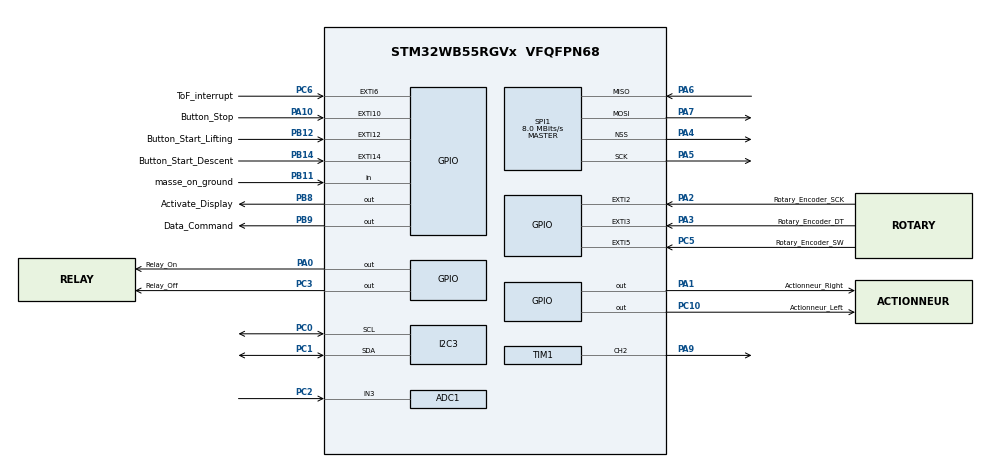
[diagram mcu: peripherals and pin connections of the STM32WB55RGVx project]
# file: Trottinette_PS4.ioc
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ADC1.Channel-0\#ChannelRegularConversion=ADC_CHANNEL_3
ADC1.ClockPrescaler=ADC_CLOCK_ASYNC_DIV4
ADC1.ContinuousConvMode=ENABLE
ADC1.DMAContinuousRequests=DISABLE
ADC1.NbrOfConversionFlag=1
ADC1.OffsetNumber-0\#ChannelRegularConversion=ADC_OFFSET_NONE
ADC1.Overrun=ADC_OVR_DATA_OVERWRITTEN
ADC1.Rank-0\#ChannelRegularConversion=1
ADC1.SamplingTime-0\#ChannelRegularConversion=ADC_SAMPLETIME_2CYCLES_5
ADC1.master=1
Dma.ADC1.0.Direction=DMA_PERIPH_TO_MEMORY
Dma.ADC1.0.EventEnable=DISABLE
Dma.ADC1.0.Instance=DMA1_Channel1
Dma.ADC1.0.MemDataAlignment=DMA_MDATAALIGN_HALFWORD
Dma.ADC1.0.MemInc=DMA_MINC_ENABLE
Dma.ADC1.0.Mode=DMA_CIRCULAR
Dma.ADC1.0.PeriphDataAlignment=DMA_PDATAALIGN_HALFWORD
Dma.ADC1.0.PeriphInc=DMA_PINC_DISABLE
Dma.ADC1.0.Polarity=HAL_DMAMUX_REQ_GEN_RISING
Dma.ADC1.0.Priority=DMA_PRIORITY_LOW
Dma.ADC1.0.RequestNumber=1
Dma.ADC1.0.SignalID=NONE
Dma.ADC1.0.SyncEnable=DISABLE
Dma.ADC1.0.SyncPolarity=HAL_DMAMUX_SYNC_NO_EVENT
Dma.ADC1.0.SyncRequestNumber=1
Dma.ADC1.0.SyncSignalID=NONE
Dma.Request0=ADC1
I2C3.Timing=0x00B07CB4
Mcu.Family=STM32WB
Mcu.Name=STM32WB55RGVx
Mcu.Package=VFQFPN68
NVIC.DMA1_Channel1_IRQn=true\:0\:0\:false\:false\:true\:false\:true\:true
NVIC.EXTI0_IRQn=true\:0\:0\:false\:false\:true\:true\:true\:true
NVIC.EXTI15_10_IRQn=true\:0\:0\:false\:false\:true\:true\:true\:true
NVIC.EXTI1_IRQn=true\:0\:0\:false\:false\:true\:true\:true\:true
NVIC.EXTI2_IRQn=true\:0\:0\:false\:false\:true\:true\:true\:true
NVIC.EXTI3_IRQn=true\:0\:0\:false\:false\:true\:true\:true\:true
NVIC.EXTI4_IRQn=true\:0\:0\:false\:false\:true\:true\:true\:true
NVIC.EXTI9_5_IRQn=true\:0\:0\:false\:false\:true\:true\:true\:true
NVIC.PriorityGroup=NVIC_PRIORITYGROUP_4
NVIC.SPI1_IRQn=true\:0\:0\:false\:false\:true\:true\:true\:true
NVIC.TIM2_IRQn=true\:0\:0\:false\:false\:true\:true\:true\:true
OSC_IN.GPIO_Label=RCC_OSC_IN
OSC_IN.Signal=RCC_OSC_IN
OSC_OUT.GPIO_Label=RCC_OSC_OUT
OSC_OUT.Signal=RCC_OSC_OUT
P-NUCLEO-WB55-NUCLEO.BUTTON=1
P-NUCLEO-WB55-NUCLEO.BUTTON2=1
P-NUCLEO-WB55-NUCLEO.BUTTON3=1
P-NUCLEO-WB55-NUCLEO.LD1=true
P-NUCLEO-WB55-NUCLEO.LD2=true
P-NUCLEO-WB55-NUCLEO.LD3=true
P-NUCLEO-WB55-NUCLEO.VCP=true
PA0.GPIO_Label=Relay_On
PA0.Signal=GPIO_Output
PA1.GPIO_Label=Actionneur_Right
PA1.Signal=GPIO_Output
PA10.GPIO_Label=Button_Stop
PA10.GPIO_ModeDefaultEXTI=GPIO_MODE_IT_FALLING
PA10.GPIO_PuPd=GPIO_PULLUP
PA10.Signal=GPXTI10
PA11.GPIO_Label=USB_DM
PA11.Signal=USB_DM
PA12.GPIO_Label=USB_DP
PA12.Signal=USB_DP
PA13.GPIO_Label=JTMS
PA13.Signal=SYS_JTMS-SWDIO
PA14.GPIO_Label=JTCK
PA14.Signal=SYS_JTCK-SWCLK
PA2.GPIO_Label=Rotary_Encoder_SCK
PA2.GPIO_ModeDefaultEXTI=GPIO_MODE_IT_RISING_FALLING
PA2.GPIO_PuPd=GPIO_PULLUP
PA2.Signal=GPXTI2
PA3.GPIO_Label=Rotary_Encoder_DT
PA3.GPIO_ModeDefaultEXTI=GPIO_MODE_IT_RISING_FALLING
PA3.GPIO_PuPd=GPIO_PULLUP
PA3.Signal=GPXTI3
PA4.Mode=NSS_Signal_Hard_Output
PA4.Signal=SPI1_NSS
PA5.Mode=Full_Duplex_Master
PA5.Signal=SPI1_SCK
PA6.Mode=Full_Duplex_Master
PA6.Signal=SPI1_MISO
PA7.Mode=Full_Duplex_Master
PA7.Signal=SPI1_MOSI
PA9.Signal=S_TIM1_CH2
PB11.GPIO_Label=masse_on_ground
PB11.Signal=GPIO_Input
PB12.GPIO_Label=Button_Start_Lifting
PB12.GPIO_ModeDefaultEXTI=GPIO_MODE_IT_FALLING
PB12.GPIO_PuPd=GPIO_PULLUP
PB12.Signal=GPXTI12
PB14.GPIO_Label=Button_Start_Descent
PB14.GPIO_ModeDefaultEXTI=GPIO_MODE_IT_FALLING
PB14.GPIO_PuPd=GPIO_PULLUP
PB14.Signal=GPXTI14
PB3.GPIO_Label=JTDO
PB3.Signal=SYS_JTDO-SWO
PB6.Signal=USART1_TX
PB7.Signal=USART1_RX
PB8.GPIO_Label=Activate_Display
PB8.Signal=GPIO_Output
PB9.GPIO_Label=Data_Command
PB9.Signal=GPIO_Output
PC0.Mode=I2C
PC0.Signal=I2C3_SCL
PC1.Mode=I2C
PC1.Signal=I2C3_SDA
PC10.GPIO_Label=Actionneur_Left
PC10.Signal=GPIO_Output
PC13.GPIO_Label=SYS_WKUP2
PC13.Signal=SYS_WKUP2
PC14-OSC32_IN.GPIO_Label=RCC_OSC32_IN
PC14-OSC32_IN.Signal=RCC_OSC32_IN
PC15-OSC32_OUT.GPIO_Label=RCC_OSC32_OUT
PC15-OSC32_OUT.Signal=RCC_OSC32_OUT
PC2.Signal=ADCx_IN3
PC3.GPIO_Label=Relay_Off
PC3.Signal=GPIO_Output
PC5.GPIO_Label=Rotary_Encoder_SW
PC5.GPIO_ModeDefaultEXTI=GPIO_MODE_IT_FALLING
PC5.GPIO_PuPd=GPIO_PULLUP
PC5.Signal=GPXTI5
PC6.GPIO_Label=ToF_interrupt
PC6.GPIO_ModeDefaultEXTI=GPIO_MODE_IT_FALLING
PC6.GPIO_PuPd=GPIO_PULLUP
PC6.Signal=GPXTI6
ProjectManager.HeapSize=0x200
ProjectManager.StackSize=0x400
ProjectManager.TargetToolchain=STM32CubeIDE
RCC.ADCCLockSelection=RCC_ADCCLKSOURCE_SYSCLK
RCC.ADCFreq_Value=32000000
RCC.AHBFreq_Value=32000000
RCC.APB1Freq_Value=32000000
RCC.APB1TimFreq_Value=32000000
RCC.APB2Freq_Value=32000000
RCC.APB2TimFreq_Value=32000000
RCC.APB3Freq_Value=16000000
RCC.CortexFreq_Value=32000000
RCC.HCLKFreq_Value=32000000
RCC.HSE_VALUE=32000000
RCC.HSI48_VALUE=48000000
RCC.HSI_VALUE=16000000
RCC.LSE_VALUE=32768
RCC.MSIClockRange=RCC_MSIRANGE_10
RCC.PLLM=RCC_PLLM_DIV2
RCC.PLLSAI1N=6
RCC.SMPSCLockSelection=RCC_SMPSCLKSOURCE_HSI
RCC.SMPSCLockSelectionVirtual=RCC_SMPSCLKSOURCE_HSI
RCC.SMPSCLockSelectionVirtualVirtual=RCC_SMPSCLKSOURCE_HSI
RCC.SMPSDivider=1
RCC.SYSCLKFreq_VALUE=32000000
RCC.USBFreq_Value=48000000
RCC.VCOOutputFreq_Value=128000000
SH.ADCx_IN3.0=ADC1_IN3,IN3-Single-Ended
SH.S_TIM1_CH2.0=TIM1_CH2,PWM Generation2 CH2
SPI1.BaudRatePrescaler=SPI_BAUDRATEPRESCALER_4
SPI1.CalculateBaudRate=8.0 MBits/s
SPI1.DataSize=SPI_DATASIZE_8BIT
SPI1.Direction=SPI_DIRECTION_2LINES
SPI1.Mode=SPI_MODE_MASTER
SPI1.VirtualNSS=VM_NSSHARD
SPI1.VirtualType=VM_MASTER
TIM1.Channel-PWM\ Generation2\ CH2=TIM_CHANNEL_2
TIM1.Period=999
TIM1.Prescaler=63
TIM2.Period=9
TIM2.Prescaler=3199
VP_MEMORYMAP_VS_MEMORYMAP.Mode=CurAppReg
VP_P-NUCLEO-WB55-NUCLEO_VS_BSP_COMMON.Mode=COMMON
VP_TIM2_VS_ClockSourceINT.Mode=Internal
board=P-NUCLEO-WB55-NUCLEO

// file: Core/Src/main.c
/* USER CODE BEGIN Header */
/**
  ******************************************************************************
  * @file           : main.c
  * @brief          : Main program body
  ******************************************************************************
  * @attention
  *
  * Copyright (c) 2025 STMicroelectronics.
  * All rights reserved.
  *
  * This software is licensed under terms that can be found in the LICENSE file
  * in the root directory of this software component.
  * If no LICENSE file comes with this software, it is provided AS-IS.
  *
  ******************************************************************************
  */
/* USER CODE END Header */
#include "main.h"

/* USER CODE BEGIN Includes */
#include "application.h"
/* USER CODE END Includes */

COM_InitTypeDef BspCOMInit;
ADC_HandleTypeDef hadc1;
DMA_HandleTypeDef hdma_adc1;

I2C_HandleTypeDef hi2c3;

SPI_HandleTypeDef hspi1;

TIM_HandleTypeDef htim1;
TIM_HandleTypeDef htim2;

void SystemClock_Config(void);
void PeriphCommonClock_Config(void);
static void MX_GPIO_Init(void);
static void MX_DMA_Init(void);
static void MX_SPI1_Init(void);
static void MX_TIM2_Init(void);
static void MX_ADC1_Init(void);
static void MX_I2C3_Init(void);
static void MX_TIM1_Init(void);

int main(void)
{

  /* MCU Configuration--------------------------------------------------------*/

  /* Reset of all peripherals, Initializes the Flash interface and the Systick. */
  HAL_Init();

  /* Configure the system clock */
  SystemClock_Config();

  /* Configure the peripherals common clocks */
  PeriphCommonClock_Config();

  /* Initialize all configured peripherals */
  MX_GPIO_Init();
  MX_DMA_Init();
  MX_SPI1_Init();
  MX_TIM2_Init();
  MX_ADC1_Init();
  MX_I2C3_Init();
  MX_TIM1_Init();

  /* Initialize leds */
  BSP_LED_Init(LED_BLUE);
  BSP_LED_Init(LED_GREEN);
  BSP_LED_Init(LED_RED);

  /* Initialize USER push-button, will be used to trigger an interrupt each time it's pressed.*/
  BSP_PB_Init(BUTTON_SW1, BUTTON_MODE_EXTI);
  BSP_PB_Init(BUTTON_SW2, BUTTON_MODE_EXTI);
  BSP_PB_Init(BUTTON_SW3, BUTTON_MODE_EXTI);

  /* Initialize COM1 port (115200, 8 bits (7-bit data + 1 stop bit), no parity */
  BspCOMInit.BaudRate   = 115200;
  BspCOMInit.WordLength = COM_WORDLENGTH_8B;
  BspCOMInit.StopBits   = COM_STOPBITS_1;
  BspCOMInit.Parity     = COM_PARITY_NONE;
  BspCOMInit.HwFlowCtl  = COM_HWCONTROL_NONE;
  if (BSP_COM_Init(COM1, &BspCOMInit) != BSP_ERROR_NONE)
  {
    Error_Handler();
  }

  /* Infinite loop */
  /* USER CODE BEGIN WHILE */
  application();
  while (1)
  {

    /* USER CODE END WHILE */

  }
}

void SystemClock_Config(void)
{
  RCC_OscInitTypeDef RCC_OscInitStruct = {0};
  RCC_ClkInitTypeDef RCC_ClkInitStruct = {0};

  /** Configure the main internal regulator output voltage
  */
  __HAL_PWR_VOLTAGESCALING_CONFIG(PWR_REGULATOR_VOLTAGE_SCALE1);

  /** Initializes the RCC Oscillators according to the specified parameters
  * in the RCC_OscInitTypeDef structure.
  */
  RCC_OscInitStruct.OscillatorType = RCC_OSCILLATORTYPE_HSI|RCC_OSCILLATORTYPE_MSI;
  RCC_OscInitStruct.HSIState = RCC_HSI_ON;
  RCC_OscInitStruct.MSIState = RCC_MSI_ON;
  RCC_OscInitStruct.HSICalibrationValue = RCC_HSICALIBRATION_DEFAULT;
  RCC_OscInitStruct.MSICalibrationValue = RCC_MSICALIBRATION_DEFAULT;
  RCC_OscInitStruct.MSIClockRange = RCC_MSIRANGE_10;
  RCC_OscInitStruct.PLL.PLLState = RCC_PLL_NONE;
  if (HAL_RCC_OscConfig(&RCC_OscInitStruct) != HAL_OK)
  {
    Error_Handler();
  }

  /** Configure the SYSCLKSource, HCLK, PCLK1 and PCLK2 clocks dividers
  */
  RCC_ClkInitStruct.ClockType = RCC_CLOCKTYPE_HCLK4|RCC_CLOCKTYPE_HCLK2
                              |RCC_CLOCKTYPE_HCLK|RCC_CLOCKTYPE_SYSCLK
                              |RCC_CLOCKTYPE_PCLK1|RCC_CLOCKTYPE_PCLK2;
  RCC_ClkInitStruct.SYSCLKSource = RCC_SYSCLKSOURCE_MSI;
  RCC_ClkInitStruct.AHBCLKDivider = RCC_SYSCLK_DIV1;
  RCC_ClkInitStruct.APB1CLKDivider = RCC_HCLK_DIV1;
  RCC_ClkInitStruct.APB2CLKDivider = RCC_HCLK_DIV1;
  RCC_ClkInitStruct.AHBCLK2Divider = RCC_SYSCLK_DIV1;
  RCC_ClkInitStruct.AHBCLK4Divider = RCC_SYSCLK_DIV1;

  if (HAL_RCC_ClockConfig(&RCC_ClkInitStruct, FLASH_LATENCY_1) != HAL_OK)
  {
    Error_Handler();
  }
}

void PeriphCommonClock_Config(void)
{
  RCC_PeriphCLKInitTypeDef PeriphClkInitStruct = {0};

  /** Initializes the peripherals clock
  */
  PeriphClkInitStruct.PeriphClockSelection = RCC_PERIPHCLK_SMPS;
  PeriphClkInitStruct.SmpsClockSelection = RCC_SMPSCLKSOURCE_HSI;
  PeriphClkInitStruct.SmpsDivSelection = RCC_SMPSCLKDIV_RANGE0;

  if (HAL_RCCEx_PeriphCLKConfig(&PeriphClkInitStruct) != HAL_OK)
  {
    Error_Handler();
  }
}

static void MX_ADC1_Init(void)
{

  ADC_ChannelConfTypeDef sConfig = {0};

  /** Common config
  */
  hadc1.Instance = ADC1;
  hadc1.Init.ClockPrescaler = ADC_CLOCK_ASYNC_DIV4;
  hadc1.Init.Resolution = ADC_RESOLUTION_12B;
  hadc1.Init.DataAlign = ADC_DATAALIGN_RIGHT;
  hadc1.Init.ScanConvMode = ADC_SCAN_DISABLE;
  hadc1.Init.EOCSelection = ADC_EOC_SINGLE_CONV;
  hadc1.Init.LowPowerAutoWait = DISABLE;
  hadc1.Init.ContinuousConvMode = ENABLE;
  hadc1.Init.NbrOfConversion = 1;
  hadc1.Init.DiscontinuousConvMode = DISABLE;
  hadc1.Init.ExternalTrigConv = ADC_SOFTWARE_START;
  hadc1.Init.ExternalTrigConvEdge = ADC_EXTERNALTRIGCONVEDGE_NONE;
  hadc1.Init.DMAContinuousRequests = DISABLE;
  hadc1.Init.Overrun = ADC_OVR_DATA_OVERWRITTEN;
  hadc1.Init.OversamplingMode = DISABLE;
  if (HAL_ADC_Init(&hadc1) != HAL_OK)
  {
    Error_Handler();
  }

  /** Configure Regular Channel
  */
  sConfig.Channel = ADC_CHANNEL_3;
  sConfig.Rank = ADC_REGULAR_RANK_1;
  sConfig.SamplingTime = ADC_SAMPLETIME_2CYCLES_5;
  sConfig.SingleDiff = ADC_SINGLE_ENDED;
  sConfig.OffsetNumber = ADC_OFFSET_NONE;
  sConfig.Offset = 0;
  if (HAL_ADC_ConfigChannel(&hadc1, &sConfig) != HAL_OK)
  {
    Error_Handler();
  }

}

static void MX_I2C3_Init(void)
{

  hi2c3.Instance = I2C3;
  hi2c3.Init.Timing = 0x00B07CB4;
  hi2c3.Init.OwnAddress1 = 0;
  hi2c3.Init.AddressingMode = I2C_ADDRESSINGMODE_7BIT;
  hi2c3.Init.DualAddressMode = I2C_DUALADDRESS_DISABLE;
  hi2c3.Init.OwnAddress2 = 0;
  hi2c3.Init.OwnAddress2Masks = I2C_OA2_NOMASK;
  hi2c3.Init.GeneralCallMode = I2C_GENERALCALL_DISABLE;
  hi2c3.Init.NoStretchMode = I2C_NOSTRETCH_DISABLE;
  if (HAL_I2C_Init(&hi2c3) != HAL_OK)
  {
    Error_Handler();
  }

  /** Configure Analogue filter
  */
  if (HAL_I2CEx_ConfigAnalogFilter(&hi2c3, I2C_ANALOGFILTER_ENABLE) != HAL_OK)
  {
    Error_Handler();
  }

  /** Configure Digital filter
  */
  if (HAL_I2CEx_ConfigDigitalFilter(&hi2c3, 0) != HAL_OK)
  {
    Error_Handler();
  }

}

static void MX_SPI1_Init(void)
{

  /* SPI1 parameter configuration*/
  hspi1.Instance = SPI1;
  hspi1.Init.Mode = SPI_MODE_MASTER;
  hspi1.Init.Direction = SPI_DIRECTION_2LINES;
  hspi1.Init.DataSize = SPI_DATASIZE_8BIT;
  hspi1.Init.CLKPolarity = SPI_POLARITY_LOW;
  hspi1.Init.CLKPhase = SPI_PHASE_1EDGE;
  hspi1.Init.NSS = SPI_NSS_HARD_OUTPUT;
  hspi1.Init.BaudRatePrescaler = SPI_BAUDRATEPRESCALER_4;
  hspi1.Init.FirstBit = SPI_FIRSTBIT_MSB;
  hspi1.Init.TIMode = SPI_TIMODE_DISABLE;
  hspi1.Init.CRCCalculation = SPI_CRCCALCULATION_DISABLE;
  hspi1.Init.CRCPolynomial = 7;
  hspi1.Init.CRCLength = SPI_CRC_LENGTH_DATASIZE;
  hspi1.Init.NSSPMode = SPI_NSS_PULSE_ENABLE;
  if (HAL_SPI_Init(&hspi1) != HAL_OK)
  {
    Error_Handler();
  }

}

static void MX_TIM1_Init(void)
{

  TIM_MasterConfigTypeDef sMasterConfig = {0};
  TIM_OC_InitTypeDef sConfigOC = {0};
  TIM_BreakDeadTimeConfigTypeDef sBreakDeadTimeConfig = {0};

  htim1.Instance = TIM1;
  htim1.Init.Prescaler = 63;
  htim1.Init.CounterMode = TIM_COUNTERMODE_UP;
  htim1.Init.Period = 999;
  htim1.Init.ClockDivision = TIM_CLOCKDIVISION_DIV1;
  htim1.Init.RepetitionCounter = 0;
  htim1.Init.AutoReloadPreload = TIM_AUTORELOAD_PRELOAD_DISABLE;
  if (HAL_TIM_PWM_Init(&htim1) != HAL_OK)
  {
    Error_Handler();
  }
  sMasterConfig.MasterOutputTrigger = TIM_TRGO_RESET;
  sMasterConfig.MasterOutputTrigger2 = TIM_TRGO2_RESET;
  sMasterConfig.MasterSlaveMode = TIM_MASTERSLAVEMODE_DISABLE;
  if (HAL_TIMEx_MasterConfigSynchronization(&htim1, &sMasterConfig) != HAL_OK)
  {
    Error_Handler();
  }
  sConfigOC.OCMode = TIM_OCMODE_PWM1;
  sConfigOC.Pulse = 0;
  sConfigOC.OCPolarity = TIM_OCPOLARITY_HIGH;
  sConfigOC.OCNPolarity = TIM_OCNPOLARITY_HIGH;
  sConfigOC.OCFastMode = TIM_OCFAST_DISABLE;
  sConfigOC.OCIdleState = TIM_OCIDLESTATE_RESET;
  sConfigOC.OCNIdleState = TIM_OCNIDLESTATE_RESET;
  if (HAL_TIM_PWM_ConfigChannel(&htim1, &sConfigOC, TIM_CHANNEL_2) != HAL_OK)
  {
    Error_Handler();
  }
  sBreakDeadTimeConfig.OffStateRunMode = TIM_OSSR_DISABLE;
  sBreakDeadTimeConfig.OffStateIDLEMode = TIM_OSSI_DISABLE;
  sBreakDeadTimeConfig.LockLevel = TIM_LOCKLEVEL_OFF;
  sBreakDeadTimeConfig.DeadTime = 0;
  sBreakDeadTimeConfig.BreakState = TIM_BREAK_DISABLE;
  sBreakDeadTimeConfig.BreakPolarity = TIM_BREAKPOLARITY_HIGH;
  sBreakDeadTimeConfig.BreakFilter = 0;
  sBreakDeadTimeConfig.BreakAFMode = TIM_BREAK_AFMODE_INPUT;
  sBreakDeadTimeConfig.Break2State = TIM_BREAK2_DISABLE;
  sBreakDeadTimeConfig.Break2Polarity = TIM_BREAK2POLARITY_HIGH;
  sBreakDeadTimeConfig.Break2Filter = 0;
  sBreakDeadTimeConfig.Break2AFMode = TIM_BREAK_AFMODE_INPUT;
  sBreakDeadTimeConfig.AutomaticOutput = TIM_AUTOMATICOUTPUT_DISABLE;
  if (HAL_TIMEx_ConfigBreakDeadTime(&htim1, &sBreakDeadTimeConfig) != HAL_OK)
  {
    Error_Handler();
  }
  HAL_TIM_MspPostInit(&htim1);

}

static void MX_TIM2_Init(void)
{

  TIM_ClockConfigTypeDef sClockSourceConfig = {0};
  TIM_MasterConfigTypeDef sMasterConfig = {0};

  htim2.Instance = TIM2;
  htim2.Init.Prescaler = 3199;
  htim2.Init.CounterMode = TIM_COUNTERMODE_UP;
  htim2.Init.Period = 9;
  htim2.Init.ClockDivision = TIM_CLOCKDIVISION_DIV1;
  htim2.Init.AutoReloadPreload = TIM_AUTORELOAD_PRELOAD_DISABLE;
  if (HAL_TIM_Base_Init(&htim2) != HAL_OK)
  {
    Error_Handler();
  }
  sClockSourceConfig.ClockSource = TIM_CLOCKSOURCE_INTERNAL;
  if (HAL_TIM_ConfigClockSource(&htim2, &sClockSourceConfig) != HAL_OK)
  {
    Error_Handler();
  }
  sMasterConfig.MasterOutputTrigger = TIM_TRGO_RESET;
  sMasterConfig.MasterSlaveMode = TIM_MASTERSLAVEMODE_DISABLE;
  if (HAL_TIMEx_MasterConfigSynchronization(&htim2, &sMasterConfig) != HAL_OK)
  {
    Error_Handler();
  }

}

static void MX_DMA_Init(void)
{

  /* DMA controller clock enable */
  __HAL_RCC_DMAMUX1_CLK_ENABLE();
  __HAL_RCC_DMA1_CLK_ENABLE();

  /* DMA interrupt init */
  /* DMA1_Channel1_IRQn interrupt configuration */
  HAL_NVIC_SetPriority(DMA1_Channel1_IRQn, 0, 0);
  HAL_NVIC_EnableIRQ(DMA1_Channel1_IRQn);

}

static void MX_GPIO_Init(void)
{
  GPIO_InitTypeDef GPIO_InitStruct = {0};

  /* GPIO Ports Clock Enable */
  __HAL_RCC_GPIOC_CLK_ENABLE();
  __HAL_RCC_GPIOB_CLK_ENABLE();
  __HAL_RCC_GPIOA_CLK_ENABLE();

  /*Configure GPIO pin Output Level */
  HAL_GPIO_WritePin(GPIOB, Activate_Display_Pin|Data_Command_Pin, GPIO_PIN_RESET);

  /*Configure GPIO pin Output Level */
  HAL_GPIO_WritePin(GPIOC, Relay_Off_Pin|Actionneur_Left_Pin, GPIO_PIN_RESET);

  /*Configure GPIO pin Output Level */
  HAL_GPIO_WritePin(GPIOA, Relay_On_Pin|Actionneur_Right_Pin, GPIO_PIN_RESET);

  /*Configure GPIO pins : Activate_Display_Pin Data_Command_Pin */
  GPIO_InitStruct.Pin = Activate_Display_Pin|Data_Command_Pin;
  GPIO_InitStruct.Mode = GPIO_MODE_OUTPUT_PP;
  GPIO_InitStruct.Pull = GPIO_NOPULL;
  GPIO_InitStruct.Speed = GPIO_SPEED_FREQ_LOW;
  HAL_GPIO_Init(GPIOB, &GPIO_InitStruct);

  /*Configure GPIO pins : Relay_Off_Pin Actionneur_Left_Pin */
  GPIO_InitStruct.Pin = Relay_Off_Pin|Actionneur_Left_Pin;
  GPIO_InitStruct.Mode = GPIO_MODE_OUTPUT_PP;
  GPIO_InitStruct.Pull = GPIO_NOPULL;
  GPIO_InitStruct.Speed = GPIO_SPEED_FREQ_LOW;
  HAL_GPIO_Init(GPIOC, &GPIO_InitStruct);

  /*Configure GPIO pins : Relay_On_Pin Actionneur_Right_Pin */
  GPIO_InitStruct.Pin = Relay_On_Pin|Actionneur_Right_Pin;
  GPIO_InitStruct.Mode = GPIO_MODE_OUTPUT_PP;
  GPIO_InitStruct.Pull = GPIO_NOPULL;
  GPIO_InitStruct.Speed = GPIO_SPEED_FREQ_LOW;
  HAL_GPIO_Init(GPIOA, &GPIO_InitStruct);

  /*Configure GPIO pins : Rotary_Encoder_SCK_Pin Rotary_Encoder_DT_Pin */
  GPIO_InitStruct.Pin = Rotary_Encoder_SCK_Pin|Rotary_Encoder_DT_Pin;
  GPIO_InitStruct.Mode = GPIO_MODE_IT_RISING_FALLING;
  GPIO_InitStruct.Pull = GPIO_PULLUP;
  HAL_GPIO_Init(GPIOA, &GPIO_InitStruct);

  /*Configure GPIO pins : Rotary_Encoder_SW_Pin ToF_interrupt_Pin */
  GPIO_InitStruct.Pin = Rotary_Encoder_SW_Pin|ToF_interrupt_Pin;
  GPIO_InitStruct.Mode = GPIO_MODE_IT_FALLING;
  GPIO_InitStruct.Pull = GPIO_PULLUP;
  HAL_GPIO_Init(GPIOC, &GPIO_InitStruct);

  /*Configure GPIO pin : masse_on_ground_Pin */
  GPIO_InitStruct.Pin = masse_on_ground_Pin;
  GPIO_InitStruct.Mode = GPIO_MODE_INPUT;
  GPIO_InitStruct.Pull = GPIO_NOPULL;
  HAL_GPIO_Init(masse_on_ground_GPIO_Port, &GPIO_InitStruct);

  /*Configure GPIO pins : Button_Start_Lifting_Pin Button_Start_Descent_Pin */
  GPIO_InitStruct.Pin = Button_Start_Lifting_Pin|Button_Start_Descent_Pin;
  GPIO_InitStruct.Mode = GPIO_MODE_IT_FALLING;
  GPIO_InitStruct.Pull = GPIO_PULLUP;
  HAL_GPIO_Init(GPIOB, &GPIO_InitStruct);

  /*Configure GPIO pin : Button_Stop_Pin */
  GPIO_InitStruct.Pin = Button_Stop_Pin;
  GPIO_InitStruct.Mode = GPIO_MODE_IT_FALLING;
  GPIO_InitStruct.Pull = GPIO_PULLUP;
  HAL_GPIO_Init(Button_Stop_GPIO_Port, &GPIO_InitStruct);

  /*Configure GPIO pins : USB_DM_Pin USB_DP_Pin */
  GPIO_InitStruct.Pin = USB_DM_Pin|USB_DP_Pin;
  GPIO_InitStruct.Mode = GPIO_MODE_AF_PP;
  GPIO_InitStruct.Pull = GPIO_NOPULL;
  GPIO_InitStruct.Speed = GPIO_SPEED_FREQ_LOW;
  GPIO_InitStruct.Alternate = GPIO_AF10_USB;
  HAL_GPIO_Init(GPIOA, &GPIO_InitStruct);

  /* EXTI interrupt init*/
  HAL_NVIC_SetPriority(EXTI2_IRQn, 0, 0);
  HAL_NVIC_EnableIRQ(EXTI2_IRQn);

  HAL_NVIC_SetPriority(EXTI3_IRQn, 0, 0);
  HAL_NVIC_EnableIRQ(EXTI3_IRQn);

  HAL_NVIC_SetPriority(EXTI9_5_IRQn, 0, 0);
  HAL_NVIC_EnableIRQ(EXTI9_5_IRQn);

  HAL_NVIC_SetPriority(EXTI15_10_IRQn, 0, 0);
  HAL_NVIC_EnableIRQ(EXTI15_10_IRQn);

}

void Error_Handler(void)
{
  __disable_irq();
  while (1)
  {
  }
}
